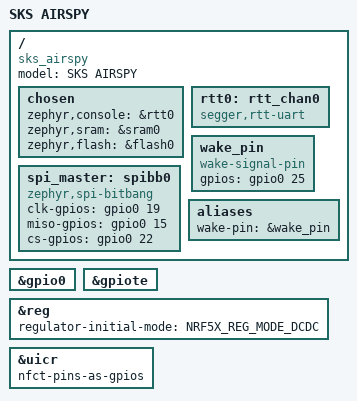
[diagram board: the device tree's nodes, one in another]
/*
 * Copyright (c) 2025 Arne Wendt (@bitmeal)
 * SPDX-License-Identifier: MPL-2.0
 */

/dts-v1/;
#include <nordic/nrf52832_qfaa.dtsi>
#include "sks_airspy-pinctrl.dtsi"
#include <zephyr/dt-bindings/input/input-event-codes.h>

/ {
	model = "SKS AIRSPY";
	compatible = "sks_airspy";

	chosen {
		zephyr,console = &rtt0;
		zephyr,sram = &sram0;
		zephyr,flash = &flash0;
	};

	rtt0: rtt_chan0 {
		compatible = "segger,rtt-uart";
		status = "okay";
	};

	wake_pin: wake_pin {
		compatible = "wake-signal-pin";
		// don't configure pull-up or down on this pin! we will dynamically configure at runtime
		gpios = <&gpio0 25 GPIO_ACTIVE_HIGH>;
	};

	spi_master: spibb0 {
		compatible = "zephyr,spi-bitbang";
		status = "okay";

		#address-cells = <1>;
		#size-cells = <0>;

		clk-gpios = <&gpio0 19 GPIO_ACTIVE_HIGH>;
		miso-gpios = <&gpio0 15 GPIO_ACTIVE_HIGH>;

		// interrupt pin:
		// depending on model, active high or low! configured at runtime
		cs-gpios = <&gpio0 22 GPIO_ACTIVE_HIGH>;
	};

	aliases {
		wake-pin = &wake_pin;
	};
};

&gpio0 {
	status = "okay";
};

&gpiote {
	status = "okay";
};

&reg {
	regulator-initial-mode = <NRF5X_REG_MODE_DCDC>;
};

&uicr {
	nfct-pins-as-gpios;
};

// // Include flash partition table.
// #include "fstab.dtsi"
